VERSION ""

NS_ :

BS_:

BU_:

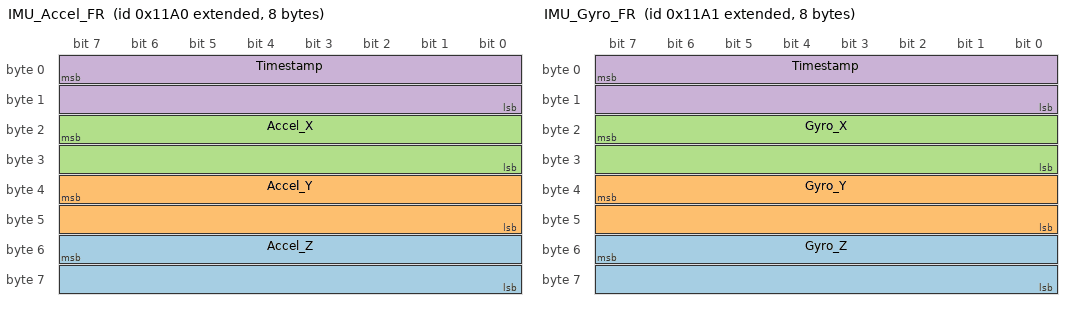
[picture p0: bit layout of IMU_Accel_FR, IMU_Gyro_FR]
BO_ 2147488160 IMU_Accel_FR: 8 Vector__XXX
 SG_ Accel_Z : 55|16@0- (0.000122,0) [-3.997696|3.997574] "g" Vector__XXX
 SG_ Accel_Y : 39|16@0- (0.000122,0) [-3.997696|3.997574] "g" Vector__XXX
 SG_ Accel_X : 23|16@0- (0.000122,0) [-3.997696|3.997574] "g" Vector__XXX
 SG_ Timestamp : 7|16@0+ (1,0) [0|65535] "" Vector__XXX

BO_ 2147488161 IMU_Gyro_FR: 8 Vector__XXX
 SG_ Gyro_Z : 55|16@0- (0.00875,0) [-286.72|286.71125] "dps" Vector__XXX
 SG_ Gyro_Y : 39|16@0- (0.00875,0) [-286.72|286.71125] "dps" Vector__XXX
 SG_ Gyro_X : 23|16@0- (0.00875,0) [-286.72|286.71125] "dps" Vector__XXX
 SG_ Timestamp : 7|16@0+ (1,0) [0|65535] "" Vector__XXX

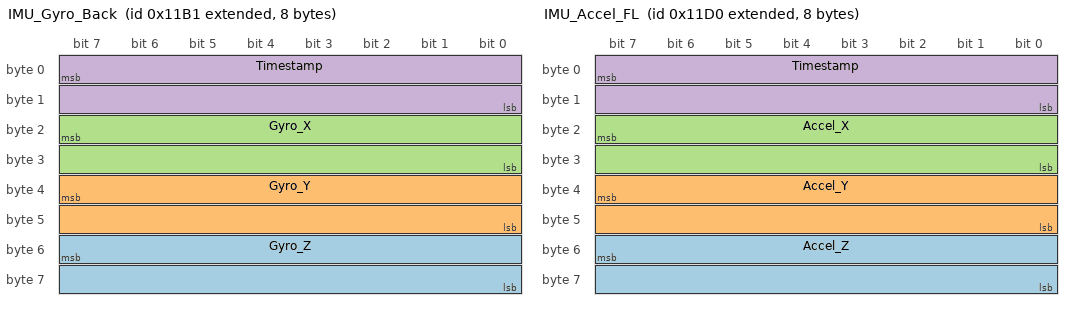
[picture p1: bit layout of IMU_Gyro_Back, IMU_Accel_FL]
BO_ 2147488177 IMU_Gyro_Back: 8 Vector__XXX
 SG_ Gyro_Z : 55|16@0- (0.00875,0) [-286.72|286.71125] "" Vector__XXX
 SG_ Gyro_Y : 39|16@0- (0.00875,0) [-286.72|286.71125] "" Vector__XXX
 SG_ Gyro_X : 23|16@0- (0.00875,0) [-286.72|286.71125] "" Vector__XXX
 SG_ Timestamp : 7|16@0+ (1,0) [0|65535] "" Vector__XXX

BO_ 2147488208 IMU_Accel_FL: 8 Vector__XXX
 SG_ Accel_Z : 55|16@0- (0.000122,0) [-3.997696|3.997574] "" Vector__XXX
 SG_ Accel_Y : 39|16@0- (0.000122,0) [-3.997696|3.997574] "" Vector__XXX
 SG_ Accel_X : 23|16@0- (0.000122,0) [-3.997696|3.997574] "" Vector__XXX
 SG_ Timestamp : 7|16@0+ (1,0) [0|65535] "" Vector__XXX

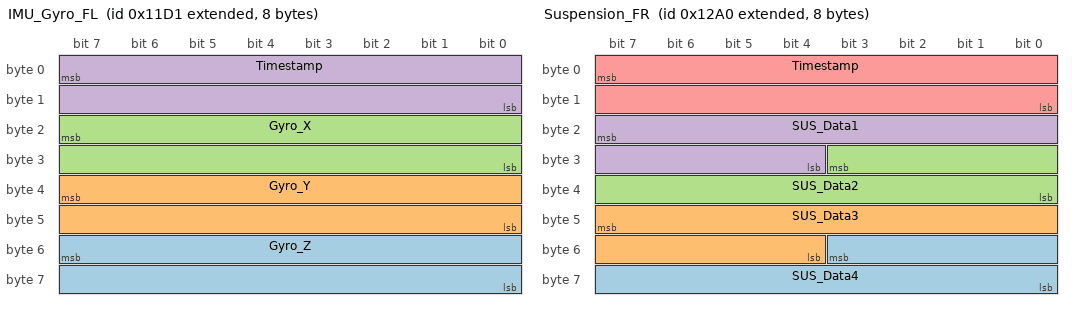
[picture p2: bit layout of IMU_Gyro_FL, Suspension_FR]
BO_ 2147488209 IMU_Gyro_FL: 8 Vector__XXX
 SG_ Gyro_Z : 55|16@0- (0.00875,0) [-286.72|286.71125] "" Vector__XXX
 SG_ Gyro_Y : 39|16@0- (0.00875,0) [-286.72|286.71125] "" Vector__XXX
 SG_ Gyro_X : 23|16@0- (0.00875,0) [-286.72|286.71125] "" Vector__XXX
 SG_ Timestamp : 7|16@0+ (1,0) [0|65535] "" Vector__XXX

BO_ 2147488416 Suspension_FR: 8 Vector__XXX
 SG_ SUS_Data4 : 51|12@0+ (1,0) [0|4095] "" Vector__XXX
 SG_ SUS_Data3 : 47|12@0+ (1,0) [0|4095] "" Vector__XXX
 SG_ SUS_Data2 : 27|12@0+ (1,0) [0|4095] "" Vector__XXX
 SG_ SUS_Data1 : 23|12@0+ (1,0) [0|4095] "" Vector__XXX
 SG_ Timestamp : 7|16@0+ (1,0) [0|65535] "" Vector__XXX

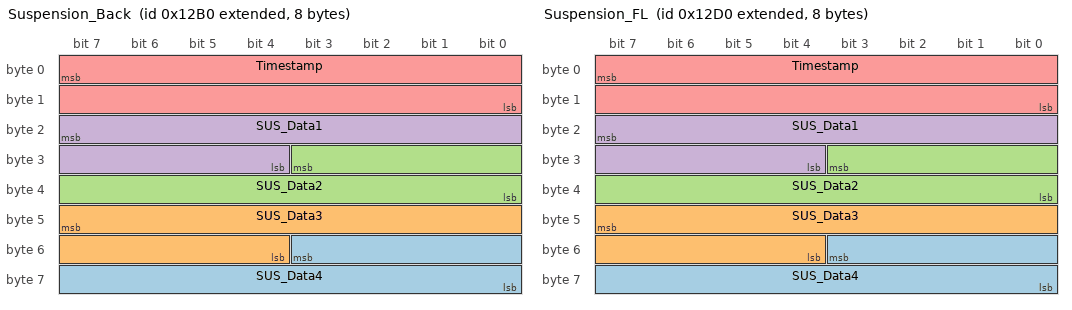
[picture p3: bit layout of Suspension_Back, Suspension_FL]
BO_ 2147488432 Suspension_Back: 8 Vector__XXX
 SG_ SUS_Data4 : 51|12@0+ (1,0) [0|4095] "" Vector__XXX
 SG_ SUS_Data3 : 47|12@0+ (1,0) [0|4095] "" Vector__XXX
 SG_ SUS_Data2 : 27|12@0+ (1,0) [0|4095] "" Vector__XXX
 SG_ SUS_Data1 : 23|12@0+ (1,0) [0|4095] "" Vector__XXX
 SG_ Timestamp : 7|16@0+ (1,0) [0|65535] "" Vector__XXX

BO_ 2147488464 Suspension_FL: 8 Vector__XXX
 SG_ SUS_Data4 : 51|12@0+ (1,0) [0|4095] "" Vector__XXX
 SG_ SUS_Data3 : 47|12@0+ (1,0) [0|4095] "" Vector__XXX
 SG_ SUS_Data2 : 27|12@0+ (1,0) [0|4095] "" Vector__XXX
 SG_ SUS_Data1 : 23|12@0+ (1,0) [0|4095] "" Vector__XXX
 SG_ Timestamp : 7|16@0+ (1,0) [0|65535] "" Vector__XXX

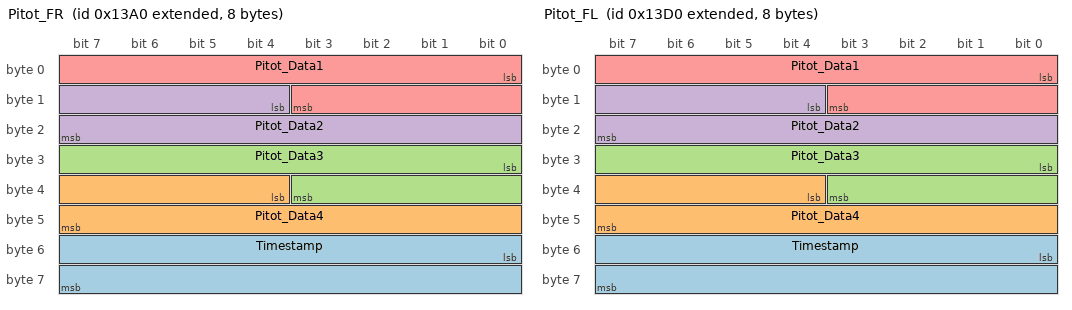
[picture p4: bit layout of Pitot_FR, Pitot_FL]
BO_ 2147488672 Pitot_FR: 8 Vector__XXX
 SG_ Timestamp : 48|16@1+ (1,0) [0|65535] "" Vector__XXX
 SG_ Pitot_Data4 : 36|12@1+ (1,0) [0|4095] "" Vector__XXX
 SG_ Pitot_Data3 : 24|12@1+ (1,0) [0|4095] "" Vector__XXX
 SG_ Pitot_Data2 : 12|12@1+ (1,0) [0|4095] "" Vector__XXX
 SG_ Pitot_Data1 : 0|12@1+ (1,0) [0|4095] "" Vector__XXX

BO_ 2147488720 Pitot_FL: 8 Vector__XXX
 SG_ Timestamp : 48|16@1+ (1,0) [0|65535] "" Vector__XXX
 SG_ Pitot_Data4 : 36|12@1+ (1,0) [0|4095] "" Vector__XXX
 SG_ Pitot_Data3 : 24|12@1+ (1,0) [0|4095] "" Vector__XXX
 SG_ Pitot_Data2 : 12|12@1+ (1,0) [0|4095] "" Vector__XXX
 SG_ Pitot_Data1 : 0|12@1+ (1,0) [0|4095] "" Vector__XXX

BO_ 2147488928 WheelRPM_FR: 8 Vector__XXX
 SG_ Timestamp : 16|16@1+ (1,0) [0|65535] "" Vector__XXX
 SG_ RPM : 0|16@1+ (1,0) [0|65535] "rpm" Vector__XXX

BO_ 2147488976 WheelRPM_FL: 8 Vector__XXX
 SG_ Timestamp : 16|16@1+ (1,0) [0|65535] "" Vector__XXX
 SG_ RPM : 0|16@1+ (1,0) [0|65535] "rpm" Vector__XXX

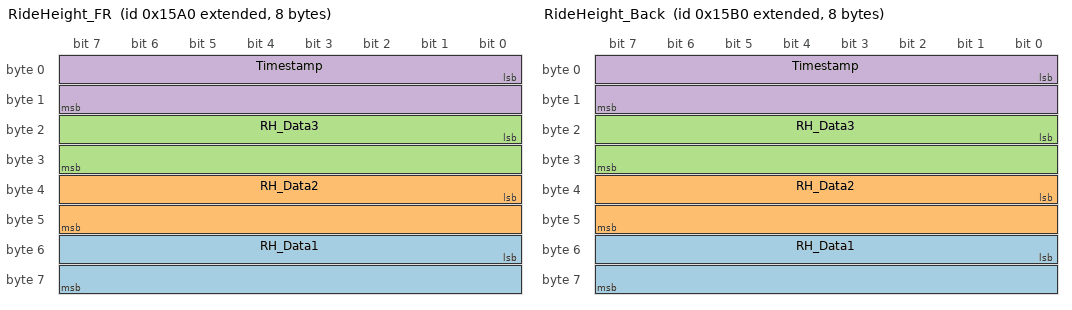
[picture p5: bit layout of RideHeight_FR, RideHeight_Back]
BO_ 2147489184 RideHeight_FR: 8 Vector__XXX
 SG_ RH_Data1 : 48|16@1+ (1,0) [0|65535] "" Vector__XXX
 SG_ RH_Data2 : 32|16@1+ (1,0) [0|65535] "" Vector__XXX
 SG_ RH_Data3 : 16|16@1+ (1,0) [0|65535] "" Vector__XXX
 SG_ Timestamp : 0|16@1+ (1,0) [0|65535] "" Vector__XXX

BO_ 2147489200 RideHeight_Back: 8 Vector__XXX
 SG_ RH_Data1 : 48|16@1+ (1,0) [0|65535] "" Vector__XXX
 SG_ RH_Data2 : 32|16@1+ (1,0) [0|65535] "" Vector__XXX
 SG_ RH_Data3 : 16|16@1+ (1,0) [0|65535] "" Vector__XXX
 SG_ Timestamp : 0|16@1+ (1,0) [0|65535] "" Vector__XXX

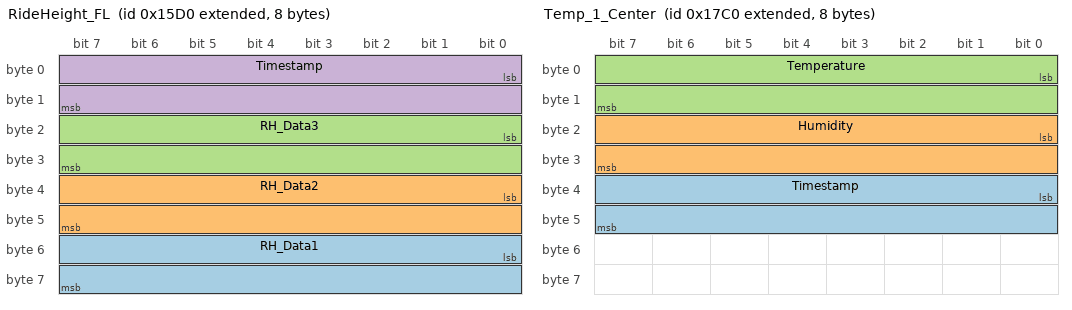
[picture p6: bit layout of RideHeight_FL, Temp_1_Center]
BO_ 2147489232 RideHeight_FL: 8 Vector__XXX
 SG_ RH_Data1 : 48|16@1+ (1,0) [0|65535] "" Vector__XXX
 SG_ RH_Data2 : 32|16@1+ (1,0) [0|65535] "" Vector__XXX
 SG_ RH_Data3 : 16|16@1+ (1,0) [0|65535] "" Vector__XXX
 SG_ Timestamp : 0|16@1+ (1,0) [0|65535] "" Vector__XXX

BO_ 2147489728 Temp_1_Center: 8 Vector__XXX
 SG_ Timestamp : 32|16@1+ (1,0) [0|65535] "" Vector__XXX
 SG_ Humidity : 16|16@1+ (1,0) [0|65535] "" Vector__XXX
 SG_ Temperature : 0|16@1+ (1,0) [0|65535] "" Vector__XXX

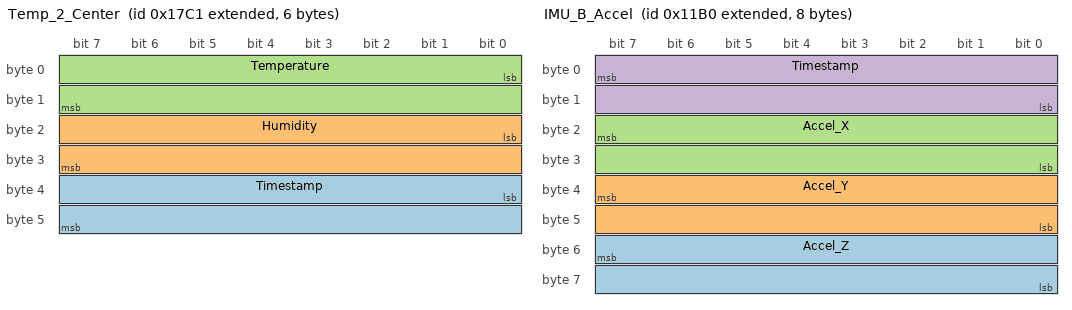
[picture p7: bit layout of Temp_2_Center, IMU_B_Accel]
BO_ 2147489729 Temp_2_Center: 6 Vector__XXX
 SG_ Timestamp : 32|16@1+ (1,0) [0|65535] "" Vector__XXX
 SG_ Humidity : 16|16@1+ (1,0) [0|65535] "" Vector__XXX
 SG_ Temperature : 0|16@1- (1,0) [-32768|32767] "" Vector__XXX

BO_ 2147489730 FR_IMU_Temp: 4 Vector__XXX
 SG_ Temperature : 23|16@0- (0.00703125,77) [-40|180] "" Vector__XXX
 SG_ Timestamp : 7|16@0+ (1,0) [0|65535] "" Vector__XXX

BO_ 2147489731 FL_IMU_Temp: 4 Vector__XXX
 SG_ Temperature : 23|16@0- (0.00703125,77) [-40|180] "" Vector__XXX
 SG_ Timestamp : 7|16@0+ (1,0) [0|65535] "" Vector__XXX

BO_ 2147489732 B_IMU_Temp: 4 Vector__XXX
 SG_ Temperature : 23|16@0- (0.00703125,77) [-40|180] "" Vector__XXX
 SG_ Timestamp : 7|16@0+ (1,0) [0|65535] "" Vector__XXX

BO_ 2147488176 IMU_B_Accel: 8 Vector__XXX
 SG_ Accel_Z : 55|16@0- (0.000122,0) [-3.997696|3.997574] "" Vector__XXX
 SG_ Accel_Y : 39|16@0- (0.000122,0) [-3.997696|3.997574] "" Vector__XXX
 SG_ Accel_X : 23|16@0- (0.000122,0) [-3.997696|3.997574] "" Vector__XXX
 SG_ Timestamp : 7|16@0+ (1,0) [0|65535] "" Vector__XXX

BO_ 2147487936 GPS_Latitude: 4 Vector__XXX
 SG_ Latitude : 0|32@1- (1e-06,0) [-90|90] "°" Vector__XXX

BO_ 2147487937 GPS_Longitude: 4 Vector__XXX
 SG_ Longitude : 0|32@1- (1e-06,0) [-180|180] "°" Vector__XXX
